# ESP32-P4 register map
Vendor: ESPRESSIF SYSTEMS (SHANGHAI) CO., LTD.; Series: ESP32 P-Series; File version: 3
CPU: RV32IMAFC r0p0, little endian, no MPU, FPU, 0 interrupt priority bits
Address unit: 32 bits
Registers are 32-bit, read-write, reset 0x0 unless marked. A register's access mark holds for its fields unless they carry their own. Offsets are from the block's base; [hi:lo] are bit positions; {n}, {i} and the like mark numbered series.

## HP_SYS — High-Power System
Base 0x500E5000
0x00 VER_DATE reset 0x20250307
  [31:0] REG_VER_DATE
0x04 CLK_EN
  [0] REG_CLK_EN
{0x10+4i} CPU_INTR_FROM_CPU{i} (i=0..3)
  [0] CPU_INTR — set 1 will triger a interrupt
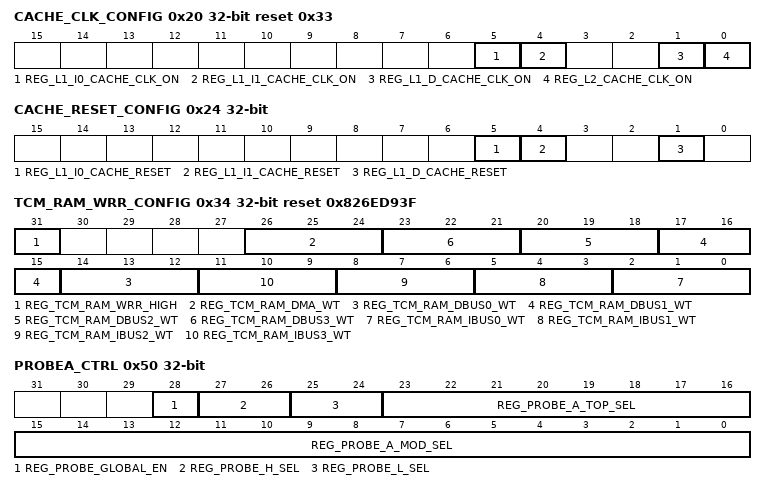
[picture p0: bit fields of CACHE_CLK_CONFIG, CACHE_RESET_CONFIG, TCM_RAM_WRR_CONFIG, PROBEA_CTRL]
0x20 CACHE_CLK_CONFIG reset 0x33
  [5] REG_L1_I0_CACHE_CLK_ON — l1 icahce0 clk enable
  [4] REG_L1_I1_CACHE_CLK_ON — l1 icahce1 clk enable
  [1] REG_L1_D_CACHE_CLK_ON — l1 dcahce clk enable
  [0] REG_L2_CACHE_CLK_ON — l2 cahce clk enable
0x24 CACHE_RESET_CONFIG
  [5] REG_L1_I0_CACHE_RESET — set 1 to reset l1 icahce0
  [4] REG_L1_I1_CACHE_RESET — set 1 to reset l1 icahce1
  [1] REG_L1_D_CACHE_RESET — set 1 to reset l1 dcahce
0x2C DMA_ADDR_CTRL
  [0] REG_SYS_DMA_ADDR_SEL — 0 means dma access extmem use 8xxx_xxxx else use 4xxx_xxxx
0x34 TCM_RAM_WRR_CONFIG reset 0x826ED93F
  [31] REG_TCM_RAM_WRR_HIGH — enable weighted round robin arbitration
  [26:24] REG_TCM_RAM_DMA_WT — weight value of dma
  [3n+14:3n+12] REG_TCM_RAM_DBUS{n}_WT (n=0..3) — weight value of dbus{n}
  [3n+2:3n] REG_TCM_RAM_IBUS{n}_WT (n=0..3) — weight value of ibus{n}
0x38 TCM_SW_PARITY_BWE_MASK
  [0] REG_TCM_SW_PARITY_BWE_MASK_CTRL — Set 1 to mask tcm bwe parity code bit
0x3C TCM_RAM_PWR_CTRL0
  [0] REG_HP_TCM_CLK_FORCE_ON — hp_tcm clk gatig force on
0x40 L2_ROM_PWR_CTRL0
  [0] REG_L2_ROM_CLK_FORCE_ON — l2_rom clk gating force on
0x50 PROBEA_CTRL
  [28] REG_PROBE_GLOBAL_EN — Set this bit to enable global debug probe in hp system.
  [27:26] REG_PROBE_H_SEL — Tihs field is used to selec probe_out[31:16]
  [25:24] REG_PROBE_L_SEL — Tihs field is used to selec probe_out[31:16]
  [23:16] REG_PROBE_A_TOP_SEL — Tihs field is used to selec module's probe_out[31:0] as probe out in a mode
  [15:0] REG_PROBE_A_MOD_SEL — Tihs field is used to selec probe_group from probe_group0 to probe_group15 for module's probe_out[31:0] in a mode
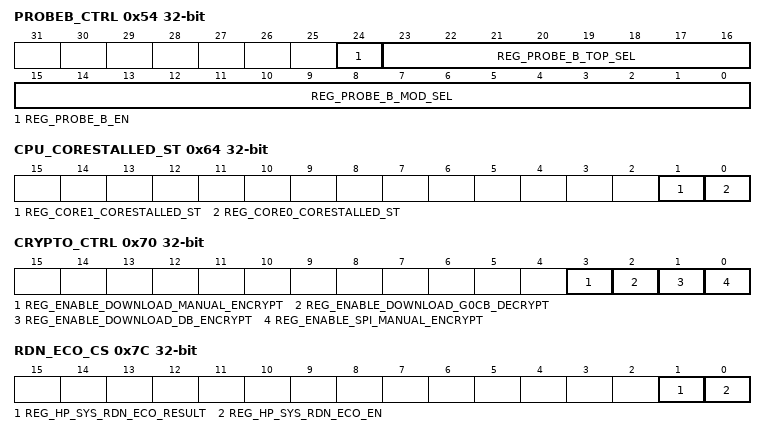
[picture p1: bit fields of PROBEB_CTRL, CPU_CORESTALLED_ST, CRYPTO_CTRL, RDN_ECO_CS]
0x54 PROBEB_CTRL
  [24] REG_PROBE_B_EN — Set this bit to enable b mode for debug probe. 1: b mode, 0: a mode.
  [23:16] REG_PROBE_B_TOP_SEL — Tihs field is used to select module's probe_out[31:0] as probe_out in b mode
  [15:0] REG_PROBE_B_MOD_SEL — Tihs field is used to selec probe_group from probe_group0 to probe_group15 for module's probe_out[31:0] in b mode.
0x5C PROBE_OUT ro
  [31:0] REG_PROBE_TOP_OUT
0x60 L2_MEM_RAM_PWR_CTRL0
  [0] REG_L2_MEM_CLK_FORCE_ON — l2ram clk_gating force on
0x64 CPU_CORESTALLED_ST ro
  [1] REG_CORE1_CORESTALLED_ST — hp core1 corestalled status
  [0] REG_CORE0_CORESTALLED_ST — hp core0 corestalled status
0x70 CRYPTO_CTRL
  [3] REG_ENABLE_DOWNLOAD_MANUAL_ENCRYPT, [2] REG_ENABLE_DOWNLOAD_G0CB_DECRYPT, [1] REG_ENABLE_DOWNLOAD_DB_ENCRYPT, [0] REG_ENABLE_SPI_MANUAL_ENCRYPT
0x74 GPIO_O_HOLD_CTRL0
  [31:0] REG_GPIO_0_HOLD_LOW — hold control for gpio47~16
0x78 GPIO_O_HOLD_CTRL1
  [8:0] REG_GPIO_0_HOLD_HIGH — hold control for gpio56~48
0x7C RDN_ECO_CS access per field
  [1] REG_HP_SYS_RDN_ECO_RESULT ro, [0] REG_HP_SYS_RDN_ECO_EN rw
0x80 CACHE_APB_POSTW_EN
  [0] REG_CACHE_APB_POSTW_EN — cache apb register interface post write enable, 1 will speed up write, but will take some time to update value to register
0x84 L2_MEM_SUBSIZE
  [1:0] REG_L2_MEM_SUB_BLKSIZE — l2mem sub block size 00=>32 01=>64 10=>128 11=>256
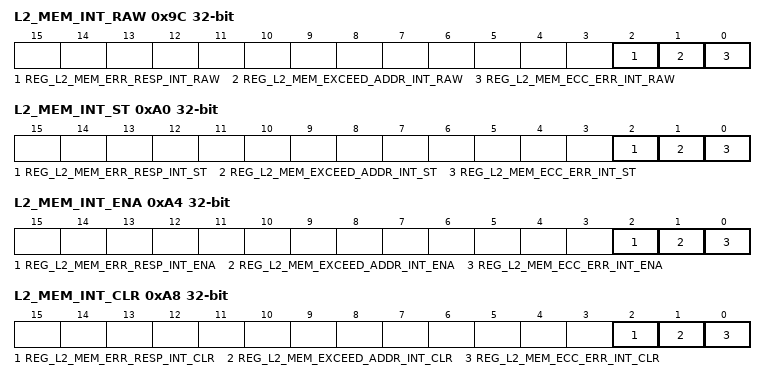
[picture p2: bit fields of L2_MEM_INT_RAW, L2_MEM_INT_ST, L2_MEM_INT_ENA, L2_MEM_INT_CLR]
0x9C L2_MEM_INT_RAW
  [2] REG_L2_MEM_ERR_RESP_INT_RAW — intr triggered when err response occurs
  [1] REG_L2_MEM_EXCEED_ADDR_INT_RAW — intr triggered when access addr exceeds 0xff9ffff at bypass mode or exceeds 0xff80000 at l2cache 128kb mode or exceeds 0xff60000 at l2cache 256kb mode
  [0] REG_L2_MEM_ECC_ERR_INT_RAW — intr triggered when two bit error detected and corrected from ecc
0xA0 L2_MEM_INT_ST ro
  [2] REG_L2_MEM_ERR_RESP_INT_ST, [1] REG_L2_MEM_EXCEED_ADDR_INT_ST, [0] REG_L2_MEM_ECC_ERR_INT_ST
0xA4 L2_MEM_INT_ENA
  [2] REG_L2_MEM_ERR_RESP_INT_ENA, [1] REG_L2_MEM_EXCEED_ADDR_INT_ENA, [0] REG_L2_MEM_ECC_ERR_INT_ENA
0xA8 L2_MEM_INT_CLR wo
  [2] REG_L2_MEM_ERR_RESP_INT_CLR, [1] REG_L2_MEM_EXCEED_ADDR_INT_CLR, [0] REG_L2_MEM_ECC_ERR_INT_CLR
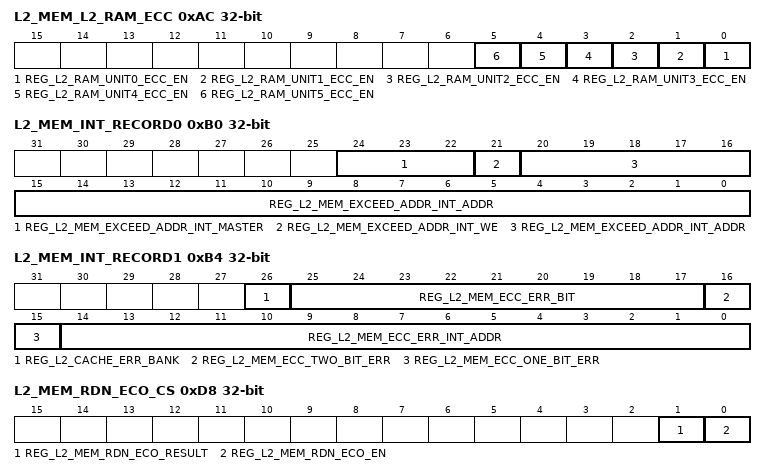
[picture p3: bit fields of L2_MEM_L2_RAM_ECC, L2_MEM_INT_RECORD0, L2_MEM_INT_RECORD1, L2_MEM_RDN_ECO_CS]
0xAC L2_MEM_L2_RAM_ECC
  [n] REG_L2_RAM_UNIT{n}_ECC_EN (n=0..5)
0xB0 L2_MEM_INT_RECORD0 ro
  [24:22] REG_L2_MEM_EXCEED_ADDR_INT_MASTER, [21] REG_L2_MEM_EXCEED_ADDR_INT_WE, [20:0] REG_L2_MEM_EXCEED_ADDR_INT_ADDR
0xB4 L2_MEM_INT_RECORD1 ro
  [26] REG_L2_CACHE_ERR_BANK, [25:17] REG_L2_MEM_ECC_ERR_BIT, [16] REG_L2_MEM_ECC_TWO_BIT_ERR, [15] REG_L2_MEM_ECC_ONE_BIT_ERR, [14:0] REG_L2_MEM_ECC_ERR_INT_ADDR
0xC4 L2_MEM_L2_CACHE_ECC
  [0] REG_L2_CACHE_ECC_EN
0xC8 L1CACHE_BUS0_ID
  [3:0] REG_L1_CACHE_BUS0_ID
0xCC L1CACHE_BUS1_ID
  [3:0] REG_L1_CACHE_BUS1_ID
0xD8 L2_MEM_RDN_ECO_CS access per field
  [1] REG_L2_MEM_RDN_ECO_RESULT ro, [0] REG_L2_MEM_RDN_ECO_EN rw
0xDC L2_MEM_RDN_ECO_LOW
  [31:0] REG_L2_MEM_RDN_ECO_LOW
0xE0 L2_MEM_RDN_ECO_HIGH reset 0xFFFFFFFF
  [31:0] REG_L2_MEM_RDN_ECO_HIGH
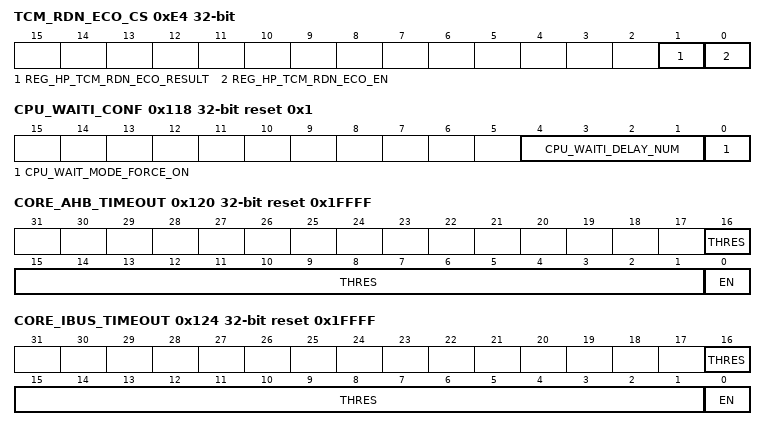
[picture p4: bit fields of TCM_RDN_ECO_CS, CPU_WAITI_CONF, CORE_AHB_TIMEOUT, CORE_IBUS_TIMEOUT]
0xE4 TCM_RDN_ECO_CS access per field
  [1] REG_HP_TCM_RDN_ECO_RESULT ro, [0] REG_HP_TCM_RDN_ECO_EN rw
0xE8 TCM_RDN_ECO_LOW
  [31:0] REG_HP_TCM_RDN_ECO_LOW
0xEC TCM_RDN_ECO_HIGH reset 0xFFFFFFFF
  [31:0] REG_HP_TCM_RDN_ECO_HIGH
0xF0 GPIO_DED_HOLD_CTRL
  [25:0] REG_GPIO_DED_HOLD — hold control for gpio63~56
0xF4 L2_MEM_SW_ECC_BWE_MASK
  [0] REG_L2_MEM_SW_ECC_BWE_MASK_CTRL — Set 1 to mask bwe hamming code bit
0xF8 USB20OTG_MEM_CTRL
  [0] REG_USB20_MEM_CLK_FORCE_ON
0xFC TCM_INT_RAW — need_des
  [31] TCM_PARITY_ERR_INT_RAW
0x100 TCM_INT_ST ro — need_des
  [31] TCM_PARITY_ERR_INT_ST
0x104 TCM_INT_ENA — need_des
  [31] TCM_PARITY_ERR_INT_ENA
0x108 TCM_INT_CLR wo — need_des
  [31] TCM_PARITY_ERR_INT_CLR
0x10C TCM_PARITY_INT_RECORD ro — need_des
  [12:0] TCM_PARITY_ERR_INT_ADDR — hp tcm_parity_err_addr
0x110 L1_CACHE_PWR_CTRL
  [5:0] REG_L1_CACHE_MEM_FO — need_des
0x114 L2_CACHE_PWR_CTRL
  [1:0] REG_L2_CACHE_MEM_FO — need_des
0x118 CPU_WAITI_CONF reset 0x1 — CPU_WAITI configuration register
  [4:1] CPU_WAITI_DELAY_NUM — This field used to set delay cycle when cpu enter waiti mode, after delay waiti_clk will close
  [0] CPU_WAIT_MODE_FORCE_ON — Set 1 to force cpu_waiti_clk enable.
0x11C CORE_DEBUG_RUNSTALL_CONF — Core Debug runstall configure register
  [0] CORE_DEBUG_RUNSTALL_ENABLE — Set this field to 1 to enable debug runstall feature between HP-core and LP-core.
0x120 CORE_AHB_TIMEOUT reset 0x1FFFF — need_des
  [16:1] THRES — This field used to set hp core0&1 ahb bus timeout threshold
  [0] EN — set this field to 1 to enable hp core0&1 ahb timeout handle
0x124 CORE_IBUS_TIMEOUT reset 0x1FFFF — need_des
  [16:1] THRES — This field used to set hp core0&1 ibus timeout threshold
  [0] EN — set this field to 1 to enable hp core0&1 ibus timeout handle
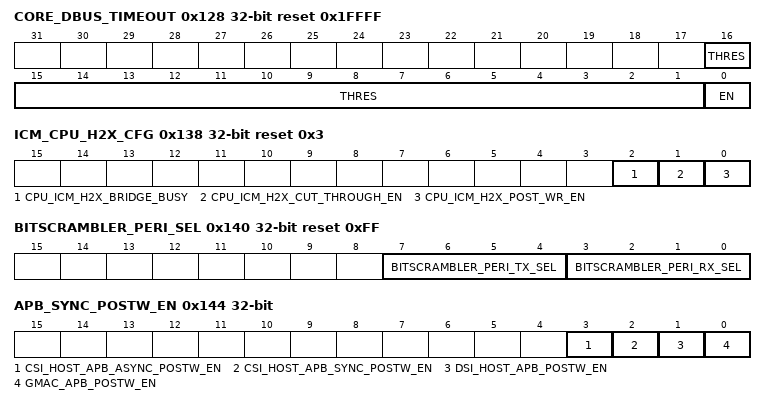
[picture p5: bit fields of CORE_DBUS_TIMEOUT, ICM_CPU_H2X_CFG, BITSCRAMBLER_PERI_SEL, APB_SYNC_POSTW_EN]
0x128 CORE_DBUS_TIMEOUT reset 0x1FFFF — need_des
  [16:1] THRES — This field used to set hp core0&1 dbus timeout threshold
  [0] EN — set this field to 1 to enable hp core0&1 dbus timeout handle
0x138 ICM_CPU_H2X_CFG access per field reset 0x3 — need_des
  [2] CPU_ICM_H2X_BRIDGE_BUSY ro — need_des
  [1] CPU_ICM_H2X_CUT_THROUGH_EN rw — need_des
  [0] CPU_ICM_H2X_POST_WR_EN rw — need_des
0x13C PERI1_APB_POSTW_EN
  [0] PERI1_APB_POSTW_EN — hp_peri1 apb register interface post write enable, 1 will speed up write, but will take some time to update value to register
0x140 BITSCRAMBLER_PERI_SEL reset 0xFF
  [7:4] BITSCRAMBLER_PERI_TX_SEL — Set this field to sel peri with DMA TX interface to connec with bitscrambler: 4'h0 : lcd_cam, 4'h1: gpspi2, 4'h2: gpspi3, 4'h3: parl_io, 4'h4: aes, 4'h5: sha, 4'h6: adc, 4'h7: i2s0, 4'h8: i2s1, 4'h9: i2s2, 4'ha: i3c_mst, 4'hb: uhci0, 4'hc: RMT, else : none
  [3:0] BITSCRAMBLER_PERI_RX_SEL — Set this field to sel peri with DMA RX interface to connec with bitscrambler: 4'h0 : lcd_cam, 4'h1: gpspi2, 4'h2: gpspi3, 4'h3: parl_io, 4'h4: aes, 4'h5: sha, 4'h6: adc, 4'h7: i2s0, 4'h8: i2s1, 4'h9: i2s2, 4'ha: i3c_mst, 4'hb: uhci0, 4'hc: RMT, else : none
0x144 APB_SYNC_POSTW_EN
  [3] CSI_HOST_APB_ASYNC_POSTW_EN, [2] CSI_HOST_APB_SYNC_POSTW_EN, [1] DSI_HOST_APB_POSTW_EN, [0] GMAC_APB_POSTW_EN
0x148 GDMA_CTRL
  [1:0] DEBUG_CH_NUM
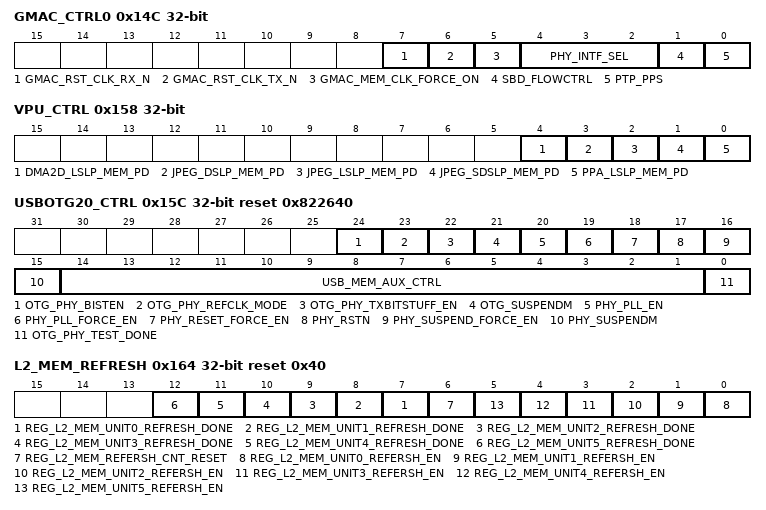
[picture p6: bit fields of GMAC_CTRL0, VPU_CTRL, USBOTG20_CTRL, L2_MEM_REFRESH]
0x14C GMAC_CTRL0 access per field
  [7] GMAC_RST_CLK_RX_N ro, [6] GMAC_RST_CLK_TX_N ro, [5] GMAC_MEM_CLK_FORCE_ON rw, [4:2] PHY_INTF_SEL rw, [1] SBD_FLOWCTRL rw, [0] PTP_PPS ro
0x150 GMAC_CTRL1 ro
  [31:0] PTP_TIMESTAMP_L
0x154 GMAC_CTRL2 ro
  [31:0] PTP_TIMESTAMP_H
0x158 VPU_CTRL
  [4] DMA2D_LSLP_MEM_PD, [3] JPEG_DSLP_MEM_PD, [2] JPEG_LSLP_MEM_PD, [1] JPEG_SDSLP_MEM_PD, [0] PPA_LSLP_MEM_PD
0x15C USBOTG20_CTRL access per field reset 0x822640
  [24] OTG_PHY_BISTEN rw, [23] OTG_PHY_REFCLK_MODE rw, [22] OTG_PHY_TXBITSTUFF_EN rw, [21] OTG_SUSPENDM rw, [20] PHY_PLL_EN rw, [19] PHY_PLL_FORCE_EN rw, [18] PHY_RESET_FORCE_EN rw, [17] PHY_RSTN rw, [16] PHY_SUSPEND_FORCE_EN rw, [15] PHY_SUSPENDM rw, [14:1] USB_MEM_AUX_CTRL rw, [0] OTG_PHY_TEST_DONE ro
0x160 TCM_ERR_RESP_CTRL — need_des
  [0] TCM_ERR_RESP_EN — Set 1 to turn on tcm error response
0x164 L2_MEM_REFRESH access per field reset 0x40
  [n+7] REG_L2_MEM_UNIT{n}_REFRESH_DONE ro (n=0..5)
  [6] REG_L2_MEM_REFERSH_CNT_RESET rw — Set 1 to reset l2mem_refresh_cnt
  [n] REG_L2_MEM_UNIT{n}_REFERSH_EN rw (n=0..5)
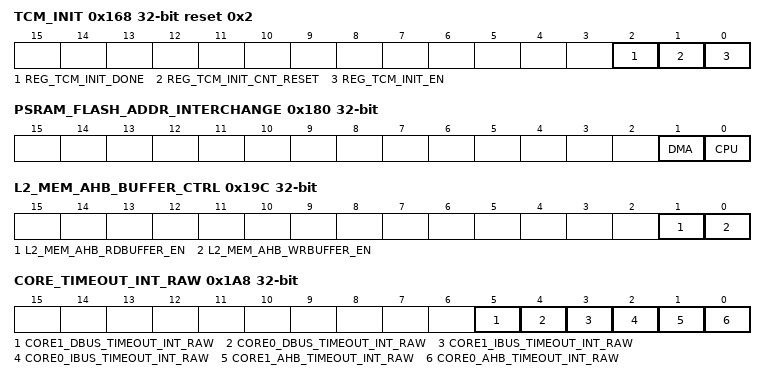
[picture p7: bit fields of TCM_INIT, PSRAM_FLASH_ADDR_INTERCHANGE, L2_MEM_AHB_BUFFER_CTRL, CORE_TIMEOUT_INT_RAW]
0x168 TCM_INIT access per field reset 0x2
  [2] REG_TCM_INIT_DONE ro
  [1] REG_TCM_INIT_CNT_RESET rw — Set 1 to reset tcm init cnt
  [0] REG_TCM_INIT_EN rw
0x16C TCM_PARITY_CHECK_CTRL — need_des
  [0] TCM_PARITY_CHECK_EN — Set 1 to turn on tcm parity check
0x170 DESIGN_FOR_VERIFICATION0 — need_des
  [31:0] DFV0 — register for DV
0x174 DESIGN_FOR_VERIFICATION1 — need_des
  [31:0] DFV1 — register for DV
0x180 PSRAM_FLASH_ADDR_INTERCHANGE — need_des
  [1] DMA — Set 1 to enable addr interchange between psram and flash in axi matrix when dma device access, lp core access and hp core access through ahb
  [0] CPU — Set 1 to enable addr interchange between psram and flash in axi matrix when hp cpu access through cache
0x188 AHB2AXI_BRESP_ERR_INT_RAW
  [0] CPU_ICM_H2X_BRESP_ERR_INT_RAW — the raw interrupt status of bresp error, triggered when if bresp err occurs in post write mode in ahb2axi.
0x18C AHB2AXI_BRESP_ERR_INT_ST ro — need_des
  [31] CPU_ICM_H2X_BRESP_ERR_INT_ST — the masked interrupt status of cpu_icm_h2x_bresp_err
0x190 AHB2AXI_BRESP_ERR_INT_ENA — need_des
  [31] CPU_ICM_H2X_BRESP_ERR_INT_ENA — Write 1 to enable cpu_icm_h2x_bresp_err int
0x194 AHB2AXI_BRESP_ERR_INT_CLR wo — need_des
  [31] CPU_ICM_H2X_BRESP_ERR_INT_CLR — Write 1 to clear cpu_icm_h2x_bresp_err int
0x198 L2_MEM_ERR_RESP_CTRL — need_des
  [0] L2_MEM_ERR_RESP_EN — Set 1 to turn on l2mem error response
0x19C L2_MEM_AHB_BUFFER_CTRL — need_des
  [1] L2_MEM_AHB_RDBUFFER_EN — Set 1 to turn on l2mem ahb rd buffer
  [0] L2_MEM_AHB_WRBUFFER_EN — Set 1 to turn on l2mem ahb wr buffer
0x1A0 CORE_DMACTIVE_LPCORE ro — need_des
  [0] CORE_DMACTIVE_LPCORE — hp core dmactive_lpcore value
0x1A4 CORE_ERR_RESP_DIS — need_des
  [2:0] CORE_ERR_RESP_DIS — Set bit0 to disable ibus err resp. Set bit1 to disable dbus err resp. Set bit 2 to disable ahb err resp.
0x1A8 CORE_TIMEOUT_INT_RAW — Hp core bus timeout interrupt raw register
  [5] CORE1_DBUS_TIMEOUT_INT_RAW — the raw interrupt status of hp core1 dbus timeout
  [4] CORE0_DBUS_TIMEOUT_INT_RAW — the raw interrupt status of hp core0 dbus timeout
  [3] CORE1_IBUS_TIMEOUT_INT_RAW — the raw interrupt status of hp core1 ibus timeout
  [2] CORE0_IBUS_TIMEOUT_INT_RAW — the raw interrupt status of hp core0 ibus timeout
  [1] CORE1_AHB_TIMEOUT_INT_RAW — the raw interrupt status of hp core1 ahb timeout
  [0] CORE0_AHB_TIMEOUT_INT_RAW — the raw interrupt status of hp core0 ahb timeout
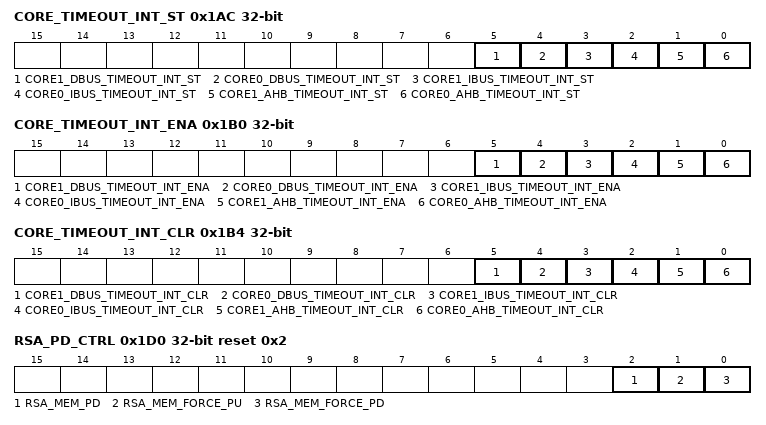
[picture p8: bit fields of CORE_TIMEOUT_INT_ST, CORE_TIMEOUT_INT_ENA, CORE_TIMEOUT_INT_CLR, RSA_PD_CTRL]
0x1AC CORE_TIMEOUT_INT_ST ro — masked interrupt register
  [5] CORE1_DBUS_TIMEOUT_INT_ST — the masked interrupt status of hp core1 dbus timeout
  [4] CORE0_DBUS_TIMEOUT_INT_ST — the masked interrupt status of hp core0 dbus timeout
  [3] CORE1_IBUS_TIMEOUT_INT_ST — the masked interrupt status of hp core1 ibus timeout
  [2] CORE0_IBUS_TIMEOUT_INT_ST — the masked interrupt status of hp core0 ibus timeout
  [1] CORE1_AHB_TIMEOUT_INT_ST — the masked interrupt status of hp core1 ahb timeout
  [0] CORE0_AHB_TIMEOUT_INT_ST — the masked interrupt status of hp core0 ahb timeout
0x1B0 CORE_TIMEOUT_INT_ENA — masked interrupt register
  [5] CORE1_DBUS_TIMEOUT_INT_ENA — Write 1 to enable hp_core1_dbus_timeout int
  [4] CORE0_DBUS_TIMEOUT_INT_ENA — Write 1 to enable hp_core0_dbus_timeout int
  [3] CORE1_IBUS_TIMEOUT_INT_ENA — Write 1 to enable hp_core1_ibus_timeout int
  [2] CORE0_IBUS_TIMEOUT_INT_ENA — Write 1 to enable hp_core0_ibus_timeout int
  [1] CORE1_AHB_TIMEOUT_INT_ENA — Write 1 to enable hp_core1_ahb_timeout int
  [0] CORE0_AHB_TIMEOUT_INT_ENA — Write 1 to enable hp_core0_ahb_timeout int
0x1B4 CORE_TIMEOUT_INT_CLR wo — interrupt clear register
  [5] CORE1_DBUS_TIMEOUT_INT_CLR — Write 1 to clear hp_core1_dbus_timeout int
  [4] CORE0_DBUS_TIMEOUT_INT_CLR — Write 1 to clear hp_core0_dbus_timeout int
  [3] CORE1_IBUS_TIMEOUT_INT_CLR — Write 1 to clear hp_core1_ibus_timeout int
  [2] CORE0_IBUS_TIMEOUT_INT_CLR — Write 1 to clear hp_core0_ibus_timeout int
  [1] CORE1_AHB_TIMEOUT_INT_CLR — Write 1 to clear hp_core1_ahb_timeout int
  [0] CORE0_AHB_TIMEOUT_INT_CLR — Write 1 to clear hp_core0_ahb_timeout int
0x1C0 GPIO_O_HYS_CTRL0
  [31:0] REG_GPIO_0_HYS_LOW — hys control for gpio47~16
0x1C4 GPIO_O_HYS_CTRL1
  [8:0] REG_GPIO_0_HYS_HIGH — hys control for gpio56~48
0x1D0 RSA_PD_CTRL reset 0x2
  [2] RSA_MEM_PD — Set this bit to force power down rsa internal memory.
  [1] RSA_MEM_FORCE_PU — Set this bit to force power up rsa internal memory
  [0] RSA_MEM_FORCE_PD — Set this bit to power down rsa internal memory.
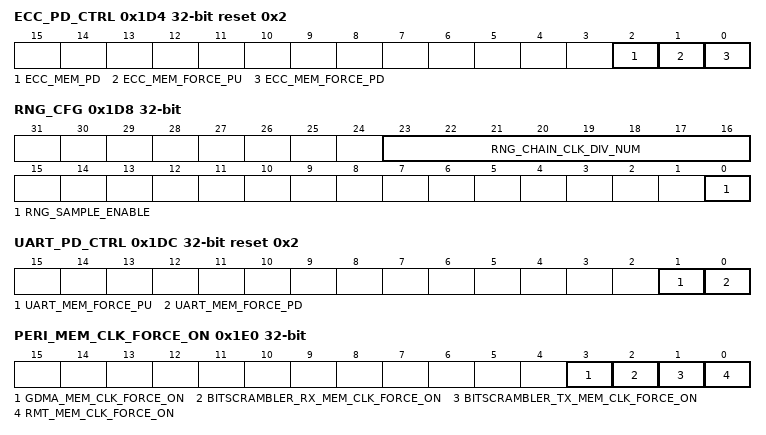
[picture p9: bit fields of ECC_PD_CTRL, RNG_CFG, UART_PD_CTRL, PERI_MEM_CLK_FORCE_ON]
0x1D4 ECC_PD_CTRL reset 0x2
  [2] ECC_MEM_PD — Set this bit to force power down ecc internal memory.
  [1] ECC_MEM_FORCE_PU — Set this bit to force power up ecc internal memory
  [0] ECC_MEM_FORCE_PD — Set this bit to power down ecc internal memory.
0x1D8 RNG_CFG
  [23:16] RNG_CHAIN_CLK_DIV_NUM — chain clk div num to pad for debug
  [0] RNG_SAMPLE_ENABLE — reserved
0x1DC UART_PD_CTRL reset 0x2 — ecc pd ctrl register
  [1] UART_MEM_FORCE_PU — Set this bit to force power up hp uart internal memory
  [0] UART_MEM_FORCE_PD — Set this bit to power down hp uart internal memory.
0x1E0 PERI_MEM_CLK_FORCE_ON — hp peri mem clk force on regpster
  [3] GDMA_MEM_CLK_FORCE_ON — Set this bit to force on mem clk in gdma
  [2] BITSCRAMBLER_RX_MEM_CLK_FORCE_ON — Set this bit to force on rx mem clk in bitscrambler
  [1] BITSCRAMBLER_TX_MEM_CLK_FORCE_ON — Set this bit to force on tx mem clk in bitscrambler
  [0] RMT_MEM_CLK_FORCE_ON — Set this bit to force on mem clk in rmt
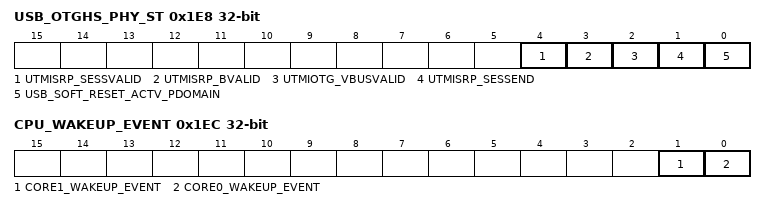
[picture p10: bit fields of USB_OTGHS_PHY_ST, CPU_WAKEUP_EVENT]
0x1E8 USB_OTGHS_PHY_ST ro — Usb otg2.0 PHY status register
  [4] UTMISRP_SESSVALID — Todo
  [3] UTMISRP_BVALID — Todo
  [2] UTMIOTG_VBUSVALID — Todo
  [1] UTMISRP_SESSEND — Todo
  [0] USB_SOFT_RESET_ACTV_PDOMAIN — Todo
0x1EC CPU_WAKEUP_EVENT — cpu wakeup event ctrl register
  [1] CORE1_WAKEUP_EVENT — Set this bit to wake up hp core1
  [0] CORE0_WAKEUP_EVENT — Set this bit to wake up hp core0
{0x1F0+4i} HP2LP_INTR_GROUP{i}_EN reset 0xFFFFFFFF (i=0..2) — HpP2LP Interrupt Enable Register Group{i}
  [31:0] H2LP_INTR_GROUP{i}_EN — Set each bit to enable corresponding peripheral interrupt to LP CPU.
0x1FC HP2LP_INTR_GROUP3_EN reset 0x3FFF — HpP2LP Interrupt Enable Register Group3
  [13:0] H2LP_INTR_GROUP3_EN — Set each bit to enable corresponding peripheral interrupt to LP CPU.
0x200 HP2LP_INTR_GROUP0_ST ro — HpP2LP Interrupt Status Register Group0
  [31:0] H2LP_INTR_GROUP0_ST — Each bit indicates the status of corresponding peripheral interrupt to LP CPU.
0x204 HP2LP_INTR_GROUP1_ST ro — HpP2LP Interrupt Enable Register Group1
  [31:0] H2LP_INTR_GROUP1_ST — Each bit indicates the status of corresponding peripheral interrupt to LP CPU.
0x208 HP2LP_INTR_GROUP2_ST ro — HpP2LP Interrupt Enable Register Group2
  [31:0] H2LP_INTR_GROUP2_ST — Each bit indicates the status of corresponding peripheral interrupt to LP CPU.
0x20C HP2LP_INTR_GROUP3_ST ro — HpP2LP Interrupt Enable Register Group3
  [13:0] H2LP_INTR_GROUP3_ST — Each bit indicates the status of corresponding peripheral interrupt to LP CPU.
{0x210+4i} HP2LP_WAKEUP_GROUP{i}_EN (i=0..2) — HpP2LP Wakeup Enable Register Group{i}
  [31:0] H2LP_WAKEUP_GROUP{i}_EN — Set each bit to enable corresponding peripheral wakeup to PMU.
0x21C HP2LP_WAKEUP_GROUP3_EN — HpP2LP Wakeup Enable Register Group3
  [13:0] H2LP_WAKEUP_GROUP3_EN — Set each bit to enable corresponding peripheral wakeup to PMU.
